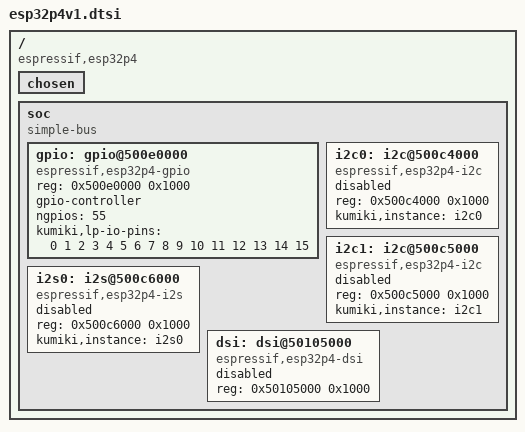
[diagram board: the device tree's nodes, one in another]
/*
 * ESP32-P4 chip revision v1.x (subset used by kumiki board definitions).
 * Hand-written (esp-metadata describes rev v3 only). Addresses from ESP-IDF
 * components/soc/esp32p4/register/hw_ver1 (reg_base.h).
 * Driven by kumiki-p4v1-hal; `kumiki,instance` names its peripheral fields.
 */

/ {
	#address-cells = <1>;
	#size-cells = <1>;
	compatible = "espressif,esp32p4";

	chosen {
	};

	soc {
		#address-cells = <1>;
		#size-cells = <1>;
		compatible = "simple-bus";
		ranges;

		gpio: gpio@500e0000 {
			compatible = "espressif,esp32p4-gpio";
			reg = <0x500e0000 0x1000>;
			gpio-controller;
			#gpio-cells = <2>;
			ngpios = <55>;
			/* LP IOs: powered in deep sleep, can wake the chip from it
			 * (soc_caps.h SOC_RTCIO_PIN_COUNT 16,
			 * SOC_GPIO_DEEP_SLEEP_WAKE_VALID_GPIO_MASK 0xFFFF). */
			kumiki,lp-io-pins = <0 1 2 3 4 5 6 7 8 9 10 11 12 13 14 15>;
		};

		i2c0: i2c@500c4000 {
			compatible = "espressif,esp32p4-i2c";
			reg = <0x500c4000 0x1000>;
			#address-cells = <1>;
			#size-cells = <0>;
			kumiki,instance = "i2c0";
			status = "disabled";
		};

		i2c1: i2c@500c5000 {
			compatible = "espressif,esp32p4-i2c";
			reg = <0x500c5000 0x1000>;
			#address-cells = <1>;
			#size-cells = <0>;
			kumiki,instance = "i2c1";
			status = "disabled";
		};

		/* I2S0 (AHB-GDMA channel 0 in kumiki-p4v1-hal). */
		i2s0: i2s@500c6000 {
			compatible = "espressif,esp32p4-i2s";
			reg = <0x500c6000 0x1000>;
			#address-cells = <1>;
			#size-cells = <0>;
			kumiki,instance = "i2s0";
			status = "disabled";
		};

		/* MIPI-DSI host + DPI bridge; the frame DMA reads a PSRAM frame buffer. */
		dsi: dsi@50105000 {
			compatible = "espressif,esp32p4-dsi";
			reg = <0x50105000 0x1000>;
			#address-cells = <1>;
			#size-cells = <0>;
			status = "disabled";
		};
	};
};
